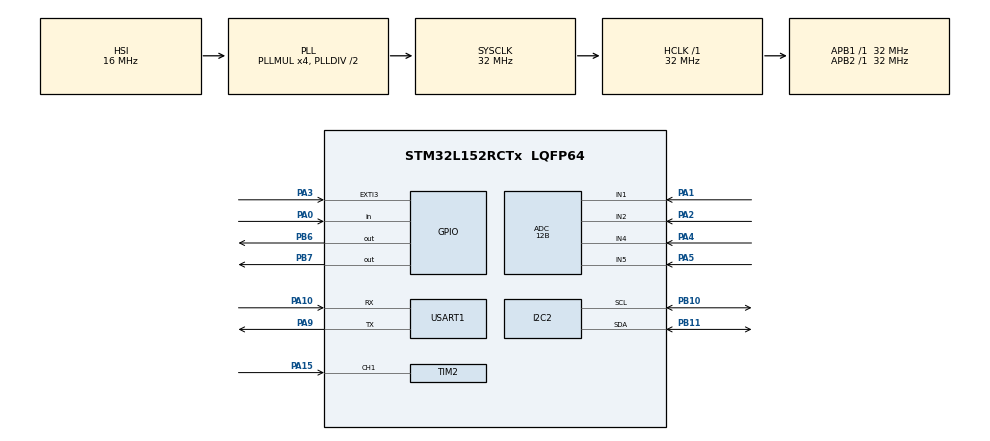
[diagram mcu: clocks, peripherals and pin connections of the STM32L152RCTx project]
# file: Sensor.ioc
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ADC.Channel-71\#ChannelRegularConversion=ADC_CHANNEL_2
ADC.ClockPrescaler=ADC_CLOCK_ASYNC_DIV4
ADC.ContinuousConvMode=DISABLE
ADC.DMAContinuousRequests=DISABLE
ADC.DataAlign=ADC_DATAALIGN_RIGHT
ADC.DiscontinuousConvMode=DISABLE
ADC.EOCSelection=ADC_EOC_SINGLE_CONV
ADC.EnableAnalogWatchDog=false
ADC.ExternalTrigConvEdge=ADC_EXTERNALTRIGCONVEDGE_NONE
ADC.InjNumberOfConversion=0
ADC.LowPowerAutoPowerOff=ADC_AUTOPOWEROFF_DISABLE
ADC.LowPowerAutoWait=ADC_AUTOWAIT_DISABLE
ADC.NbrOfConversion=1
ADC.NbrOfConversionFlag=1
ADC.Rank-71\#ChannelRegularConversion=1
ADC.Resolution=ADC_RESOLUTION_12B
ADC.SamplingTime-71\#ChannelRegularConversion=ADC_SAMPLETIME_16CYCLES
ADC.ScanConvMode=ADC_SCAN_DISABLE
I2C2.OwnAddress=64
Mcu.Family=STM32L1
Mcu.Name=STM32L152RCTx
Mcu.Package=LQFP64
NVIC.EXTI3_IRQn=true\:0\:0\:false\:false\:true
NVIC.I2C2_ER_IRQn=true\:0\:0\:false\:false\:true
NVIC.I2C2_EV_IRQn=true\:0\:0\:false\:false\:true
NVIC.PriorityGroup=NVIC_PRIORITYGROUP_4
NVIC.RTC_Alarm_IRQn=true\:0\:0\:false\:false\:true
NVIC.TIM2_IRQn=true\:0\:0\:false\:false\:true
NVIC.USART1_IRQn=true\:0\:0\:false\:false\:true
PA0-WKUP1.Signal=GPIO_Input
PA1.Mode=IN1
PA1.Signal=ADC_IN1
PA10.Mode=Asynchronous
PA10.Signal=USART1_RX
PA15.Signal=S_TIM2_CH1_ETR
PA2.Mode=IN2
PA2.Signal=ADC_IN2
PA3.GPIO_ModeDefaultEXTI=GPIO_MODE_IT_RISING_FALLING
PA3.GPIO_PuPd=GPIO_PULLUP
PA3.Signal=GPXTI3
PA4.Mode=IN4
PA4.Signal=ADC_IN4
PA5.Mode=IN5
PA5.Signal=ADC_IN5
PA9.Mode=Asynchronous
PA9.Signal=USART1_TX
PB10.Mode=I2C
PB10.Signal=I2C2_SCL
PB11.Mode=I2C
PB11.Signal=I2C2_SDA
PB6.Signal=GPIO_Output
PB7.Signal=GPIO_Output
PC14-OSC32_IN.Mode=LSE-External-Oscillator
PC14-OSC32_IN.Signal=RCC_OSC32_IN
PC15-OSC32_OUT.Mode=LSE-External-Oscillator
PC15-OSC32_OUT.Signal=RCC_OSC32_OUT
ProjectManager.HeapSize=0x200
ProjectManager.StackSize=0x400
ProjectManager.TargetToolchain=EWARM
RCC.AHBFreq_Value=32000000
RCC.APB1Freq_Value=32000000
RCC.APB1TimFreq_Value=32000000
RCC.APB2Freq_Value=32000000
RCC.APB2TimFreq_Value=32000000
RCC.HCLKFreq_Value=32000000
RCC.HSE_VALUE=24000000
RCC.HSI_VALUE=16000000
RCC.MSI_VALUE=2097000
RCC.PLLMUL=RCC_PLL_MUL4
RCC.RTCClockSelectionVirtual=RCC_RTCCLKSOURCE_LSE
RCC.SYSCLKFreq_VALUE=32000000
RCC.SYSCLKSource=RCC_SYSCLKSOURCE_PLLCLK
RCC.USBOutput=32000000
RCC.VCOOutputFreq_Value=64000000
RTC.Date=11
RTC.Hours=23
RTC.Minutes=59
RTC.Month=RTC_MONTH_MAY
RTC.Seconds=50
RTC.Year=16
SH.S_TIM2_CH1_ETR.0=TIM2_CH1,PWM_Input_1
VP_RTC_VS_RTC_Alarm_A_Intern.Mode=Alarm A
VP_TIM2_VS_ClockSourceINT.Mode=Internal
board=Sensor

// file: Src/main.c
/**
  ******************************************************************************
  * File Name          : main.c
  * Description        : Main program body
  ******************************************************************************
  *
  * COPYRIGHT(c) 2016 STMicroelectronics
  *
  * Redistribution and use in source and binary forms, with or without modification,
  * are permitted provided that the following conditions are met:
  *   1. Redistributions of source code must retain the above copyright notice,
  *      this list of conditions and the following disclaimer.
  *   2. Redistributions in binary form must reproduce the above copyright notice,
  *      this list of conditions and the following disclaimer in the documentation
  *      and/or other materials provided with the distribution.
  *   3. Neither the name of STMicroelectronics nor the names of its contributors
  *      may be used to endorse or promote products derived from this software
  *      without specific prior written permission.
  *
  * THIS SOFTWARE IS PROVIDED BY THE COPYRIGHT HOLDERS AND CONTRIBUTORS "AS IS"
  * AND ANY EXPRESS OR IMPLIED WARRANTIES, INCLUDING, BUT NOT LIMITED TO, THE
  * IMPLIED WARRANTIES OF MERCHANTABILITY AND FITNESS FOR A PARTICULAR PURPOSE ARE
  * DISCLAIMED. IN NO EVENT SHALL THE COPYRIGHT HOLDER OR CONTRIBUTORS BE LIABLE
  * FOR ANY DIRECT, INDIRECT, INCIDENTAL, SPECIAL, EXEMPLARY, OR CONSEQUENTIAL
  * DAMAGES (INCLUDING, BUT NOT LIMITED TO, PROCUREMENT OF SUBSTITUTE GOODS OR
  * SERVICES; LOSS OF USE, DATA, OR PROFITS; OR BUSINESS INTERRUPTION) HOWEVER
  * CAUSED AND ON ANY THEORY OF LIABILITY, WHETHER IN CONTRACT, STRICT LIABILITY,
  * OR TORT (INCLUDING NEGLIGENCE OR OTHERWISE) ARISING IN ANY WAY OUT OF THE USE
  * OF THIS SOFTWARE, EVEN IF ADVISED OF THE POSSIBILITY OF SUCH DAMAGE.
  *
  ******************************************************************************
  */
#include "stm32l1xx_hal.h"
#include "adc.h"
#include "i2c.h"
#include "rtc.h"
#include "tim.h"
#include "usart.h"
#include "gpio.h"

/* USER CODE BEGIN Includes */
#include "common.h"
#include "init.h"
/* USER CODE END Includes */

/* USER CODE BEGIN PV */
/* Private variables ---------------------------------------------------------*/

/* USER CODE END PV */

void SystemClock_Config(void);

/* USER CODE BEGIN PFP */
/* Private function prototypes -----------------------------------------------*/

/* USER CODE END PFP */

/* USER CODE BEGIN 0 */
#define LD3ON() HAL_GPIO_WritePin(GPIOB, GPIO_PIN_7, GPIO_PIN_SET)
#define LD3OFF() HAL_GPIO_WritePin(GPIOB, GPIO_PIN_7, GPIO_PIN_RESET)
#define LD4ON() HAL_GPIO_WritePin(GPIOB, GPIO_PIN_6, GPIO_PIN_SET)
#define LD4OFF() HAL_GPIO_WritePin(GPIOB, GPIO_PIN_6, GPIO_PIN_RESET)

/* USER CODE END 0 */

int main(void)
{

  /* MCU Configuration----------------------------------------------------------*/

  /* Reset of all peripherals, Initializes the Flash interface and the Systick. */
  HAL_Init();

  /* Configure the system clock */
  SystemClock_Config();

  /* Initialize all configured peripherals */
  MX_GPIO_Init();
  MX_I2C2_Init();
  MX_RTC_Init();
  MX_USART1_UART_Init();
  MX_ADC_Init();
  MX_TIM2_Init();

  /* USER CODE BEGIN 2 */
    HardInit();
    ParaInit();

    LD3ON();
    LD4ON();
  /* USER CODE END 2 */

  /* Infinite loop */
    while (1)
    {

  /* USER CODE BEGIN 3 */
        MainHandle();
    }
  /* USER CODE END 3 */

}

/** System Clock Configuration
*/
void SystemClock_Config(void)
{

  RCC_OscInitTypeDef RCC_OscInitStruct;
  RCC_ClkInitTypeDef RCC_ClkInitStruct;
  RCC_PeriphCLKInitTypeDef PeriphClkInit;

  __HAL_RCC_PWR_CLK_ENABLE();

  __HAL_PWR_VOLTAGESCALING_CONFIG(PWR_REGULATOR_VOLTAGE_SCALE1);

  RCC_OscInitStruct.OscillatorType = RCC_OSCILLATORTYPE_HSI|RCC_OSCILLATORTYPE_LSE;
  RCC_OscInitStruct.LSEState = RCC_LSE_ON;
  RCC_OscInitStruct.HSIState = RCC_HSI_ON;
  RCC_OscInitStruct.HSICalibrationValue = 16;
  RCC_OscInitStruct.PLL.PLLState = RCC_PLL_ON;
  RCC_OscInitStruct.PLL.PLLSource = RCC_PLLSOURCE_HSI;
  RCC_OscInitStruct.PLL.PLLMUL = RCC_PLL_MUL4;
  RCC_OscInitStruct.PLL.PLLDIV = RCC_PLL_DIV2;
  HAL_RCC_OscConfig(&RCC_OscInitStruct);

  RCC_ClkInitStruct.ClockType = RCC_CLOCKTYPE_HCLK|RCC_CLOCKTYPE_SYSCLK
                              |RCC_CLOCKTYPE_PCLK1|RCC_CLOCKTYPE_PCLK2;
  RCC_ClkInitStruct.SYSCLKSource = RCC_SYSCLKSOURCE_PLLCLK;
  RCC_ClkInitStruct.AHBCLKDivider = RCC_SYSCLK_DIV1;
  RCC_ClkInitStruct.APB1CLKDivider = RCC_HCLK_DIV1;
  RCC_ClkInitStruct.APB2CLKDivider = RCC_HCLK_DIV1;
  HAL_RCC_ClockConfig(&RCC_ClkInitStruct, FLASH_LATENCY_1);

  PeriphClkInit.PeriphClockSelection = RCC_PERIPHCLK_RTC;
  PeriphClkInit.RTCClockSelection = RCC_RTCCLKSOURCE_LSE;
  HAL_RCCEx_PeriphCLKConfig(&PeriphClkInit);

  HAL_SYSTICK_Config(HAL_RCC_GetHCLKFreq()/1000);

  HAL_SYSTICK_CLKSourceConfig(SYSTICK_CLKSOURCE_HCLK);

  /* SysTick_IRQn interrupt configuration */
  HAL_NVIC_SetPriority(SysTick_IRQn, 0, 0);
}

/************************ (C) COPYRIGHT STMicroelectronics *****END OF FILE****/
